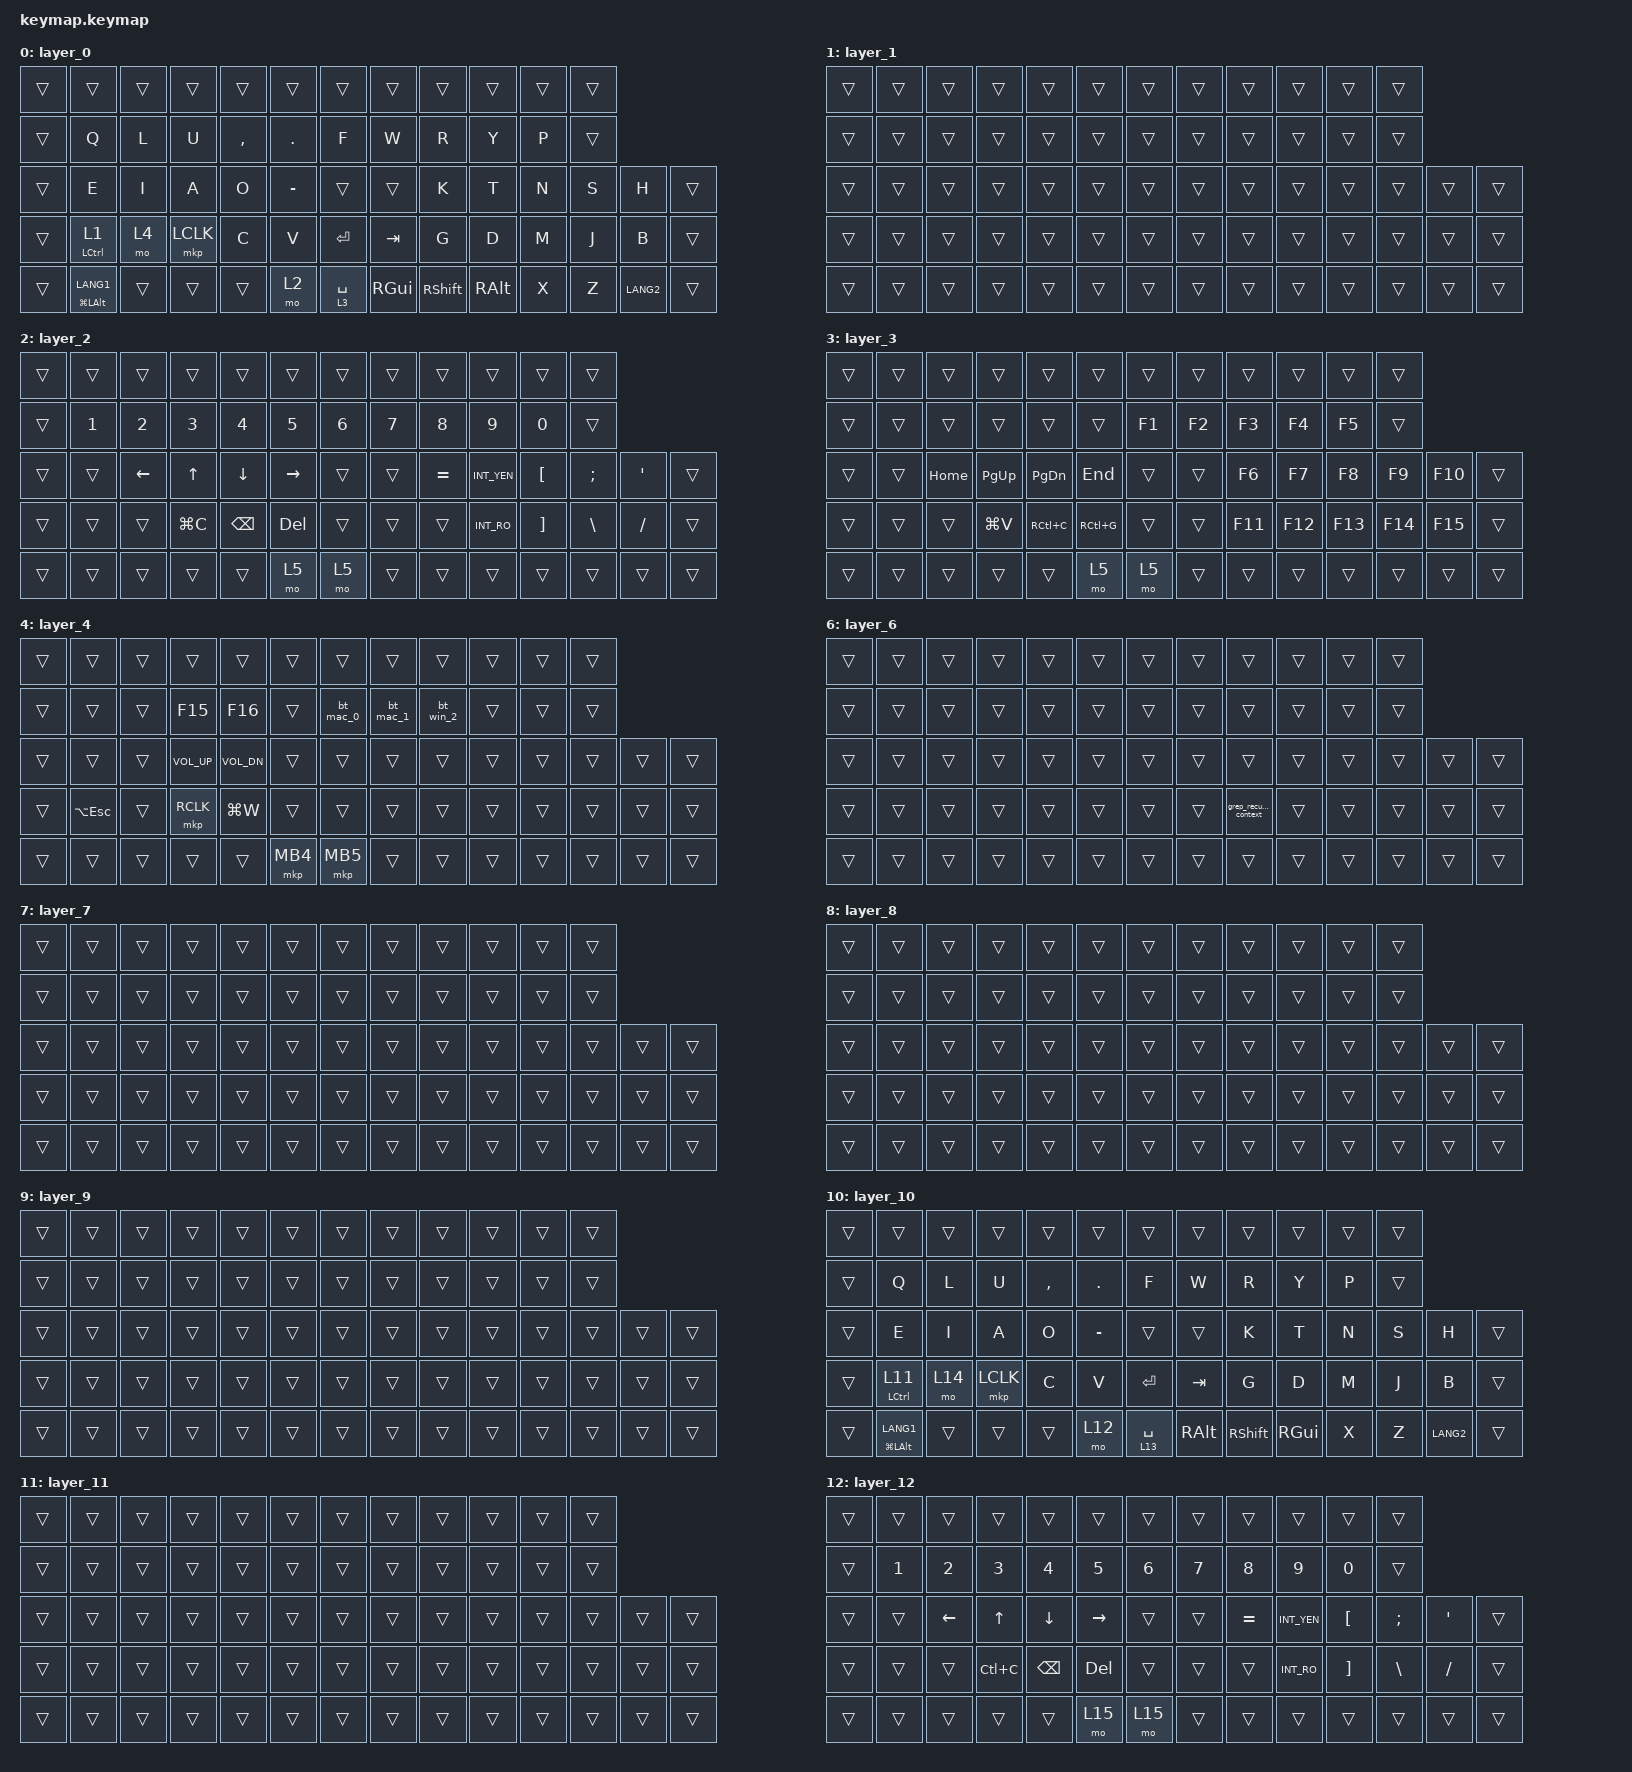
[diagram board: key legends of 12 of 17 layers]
#include <behaviors.dtsi>
#include <dt-bindings/zmk/bt.h>
#include <dt-bindings/zmk/keys.h>
#include <dt-bindings/zmk/outputs.h>
#include <dt-bindings/zmk/pointing.h>

/* ここで既存 behavior を上書き */
&mt {
    flavor = "hold-preferred";
    tapping-term-ms = <200>;
};

&lt {
    flavor = "hold-preferred";
    tapping-term-ms = <200>;
};

/ {
    behaviors {
        ctrl_or_scroll_toggle: ctrl_or_scroll_toggle {
            compatible = "zmk,behavior-hold-tap";
            #binding-cells = <2>;
            flavor = "hold-preferred";
            tapping-term-ms = <200>;
            bindings = <&kp>, <&tog>;
        };
    };

    macros {
        // Bluetooth プロファイル選択とOS別レイヤー切り替えを一度に行う。
        bt_mac_0: bt_mac_0 {
            compatible = "zmk,behavior-macro";
            #binding-cells = <0>;
            bindings = <&bt BT_SEL 0>, <&to 0>;
        };

        bt_mac_1: bt_mac_1 {
            compatible = "zmk,behavior-macro";
            #binding-cells = <0>;
            bindings = <&bt BT_SEL 1>, <&to 0>;
        };

        bt_win_2: bt_win_2 {
            compatible = "zmk,behavior-macro";
            #binding-cells = <0>;
            bindings = <&bt BT_SEL 2>, <&to 10>;
        };

        esc_eisu: esc_eisu {
            compatible = "zmk,behavior-macro";
            #binding-cells = <0>;
            bindings
                = <&macro_tap &kp ESCAPE>
                , <&macro_tap &kp LANG2>;
        };

        emacs_org_prefix: emacs_org_prefix {
            compatible = "zmk,behavior-macro";
            #binding-cells = <0>;
            bindings = <&macro_tap &kp LC(C) &kp LC(X)>;
        };

        // RDP 全画面でもローカルの仮想デスクトップを切り替える。
        // Ctrl、Altを先に押してからHomeを短く入力する（診断ブランチで短押し成功）。
        rdp_desktop_left: rdp_desktop_left {
            compatible = "zmk,behavior-macro";
            #binding-cells = <0>;
            wait-ms = <40>;
            tap-ms = <40>;
            bindings
                = <&macro_press &kp LCTRL &kp LALT>
                , <&macro_tap &kp HOME>
                , <&macro_release &kp LALT>
                , <&macro_wait_time 0>
                , <&kp LCTRL>
                , <&macro_wait_time 40>
                , <&macro_tap &kp LG(LC(LEFT))>;
        };

        rdp_desktop_right: rdp_desktop_right {
            compatible = "zmk,behavior-macro";
            #binding-cells = <0>;
            wait-ms = <40>;
            tap-ms = <40>;
            bindings
                = <&macro_press &kp LCTRL &kp LALT>
                , <&macro_tap &kp HOME>
                , <&macro_release &kp LALT>
                , <&macro_wait_time 0>
                , <&kp LCTRL>
                , <&macro_wait_time 40>
                , <&macro_tap &kp LG(LC(RIGHT))>;
        };

        grep_recursive_context: grep_recursive_context {
            compatible = "zmk,behavior-macro";
            #binding-cells = <0>;
            wait-ms = <5>;
            tap-ms = <5>;
            bindings
                = <&macro_tap &kp LANG2>
                , <&kp G &kp R &kp E &kp P>
                , <&kp SPACE>
                , <&kp MINUS &kp LS(R) &kp N &kp LS(C)>
                , <&kp SPACE &kp N2 &kp SPACE>
                , <&kp MINUS &kp MINUS &kp C &kp O &kp L &kp O &kp R &kp LS(MINUS) &kp A &kp U &kp T &kp O>
                , <&kp SPACE>;
        };
    };

    combos {
        compatible = "zmk,combos";

        ao_escape {
            bindings = <&kp ESCAPE>;
            key-positions = <12 13>;
            layers = <0 1 10 11>;
            timeout-ms = <30>;
        };

        tn_ctrl_x {
            bindings = <&kp LC(X)>;
            key-positions = <16 17>;
            layers = <0 1 10 11>;
            timeout-ms = <30>;
        };

        tn_ctrl_c {
            bindings = <&kp LC(C)>;
            key-positions = <16 17>;
            layers = <2 12>;
            timeout-ms = <30>;
        };

        tn_org_prefix {
            bindings = <&emacs_org_prefix>;
            key-positions = <16 17>;
            layers = <3 13>;
            timeout-ms = <30>;
        };

        ao_eisu_escape_eisu {
            bindings = <&esc_eisu>;
            key-positions = <12 13 39>;
            layers = <0 1 10 11>;
            timeout-ms = <30>;
        };

        aotn_escape_eisu {
            bindings = <&esc_eisu>;
            key-positions = <12 13 16 17>;
            layers = <0 1 10 11>;
            timeout-ms = <30>;
        };

        bt_clear {
            bindings = <&bt BT_CLR>;
            key-positions = <28 29>;
            layers = <3 13>;
        };
    };

    keymap {
        compatible = "zmk,keymap";

        layer_0 {
            bindings = <
                &trans  &trans  &trans  &trans  &trans  &trans  &trans  &trans  &trans  &trans  &trans  &trans
                &trans  &kp Q  &kp L  &kp U  &kp COMMA  &kp DOT  &kp F  &kp W  &kp R  &kp Y  &kp P  &trans
                &trans  &kp E  &kp I  &kp A  &kp O  &kp MINUS  &trans  &trans  &kp K  &kp T  &kp N  &kp S  &kp H  &trans
                &trans  &ctrl_or_scroll_toggle LCTRL 1  &mo 4  &mkp LCLK  &kp C  &kp V  &kp RET  &kp TAB  &kp G  &kp D  &kp M  &kp J  &kp B  &trans
                &trans  &mt LG(LALT) LANG1  &trans  &trans  &trans  &mo 2  &lt 3 SPACE  &kp RGUI  &kp RSHIFT  &kp RALT  &kp X  &kp Z  &kp LANG2  &trans
            >;
        };

        layer_1 {
            bindings = <
                &trans  &trans  &trans  &trans  &trans  &trans  &trans  &trans  &trans  &trans  &trans  &trans
                &trans  &trans  &trans  &trans  &trans  &trans  &trans  &trans  &trans  &trans  &trans  &trans
                &trans  &trans  &trans  &trans  &trans  &trans  &trans  &trans  &trans  &trans  &trans  &trans  &trans  &trans
                &trans  &trans  &trans  &trans  &trans  &trans  &trans  &trans  &trans  &trans  &trans  &trans  &trans  &trans
                &trans  &trans  &trans  &trans  &trans  &trans  &trans  &trans  &trans  &trans  &trans  &trans  &trans  &trans
            >;
        };

        layer_2 {
            bindings = <
                &trans  &trans  &trans  &trans  &trans  &trans  &trans  &trans  &trans  &trans  &trans  &trans
                &trans  &kp N1  &kp N2  &kp N3  &kp N4  &kp N5  &kp N6  &kp N7  &kp N8  &kp N9  &kp N0  &trans
                &trans  &trans  &kp LEFT  &kp UP_ARROW  &kp DOWN  &kp RIGHT  &trans  &trans  &kp EQUAL  &kp INT_YEN  &kp LBKT  &kp SEMI  &kp SQT  &trans
                &trans  &trans  &trans  &kp LG(C)  &kp BSPC  &kp DELETE  &trans  &trans  &trans  &kp INT_RO  &kp RBKT  &kp BSLH  &kp FSLH  &trans
                &trans  &trans  &trans  &trans  &trans  &mo 5  &mo 5  &trans  &trans  &trans  &trans  &trans  &trans  &trans
            >;
        };

        layer_3 {
            bindings = <
                &trans  &trans  &trans  &trans  &trans  &trans  &trans  &trans  &trans  &trans  &trans  &trans
                &trans  &trans  &trans  &trans  &trans  &trans  &kp F1  &kp F2  &kp F3  &kp F4  &kp F5  &trans
                &trans  &trans  &kp HOME  &kp PG_UP  &kp PAGE_DOWN  &kp END  &trans  &trans  &kp F6  &kp F7  &kp F8  &kp F9  &kp F10  &trans
                &trans  &trans  &trans  &kp LG(V)  &kp RC(C)  &kp RC(G)  &trans  &trans  &kp F11  &kp F12  &kp F13  &kp F14  &kp F15  &trans
                &trans  &trans  &trans  &trans  &trans  &mo 5  &mo 5  &trans  &trans  &trans  &trans  &trans  &trans  &trans
            >;
        };

        layer_4 {
            bindings = <
                &trans  &trans  &trans  &trans  &trans  &trans  &trans  &trans  &trans  &trans  &trans  &trans
                &trans  &trans  &trans  &kp F15  &kp F16  &trans  &bt_mac_0  &bt_mac_1  &bt_win_2  &trans  &trans  &trans
                &trans  &trans  &trans  &kp K_VOL_UP  &kp K_VOL_DN  &trans  &trans  &trans  &trans  &trans  &trans  &trans  &trans  &trans
                &trans  &kp LA(ESCAPE)  &trans  &mkp RCLK  &kp LG(W)  &trans  &trans  &trans  &trans  &trans  &trans  &trans  &trans  &trans
                &trans  &trans  &trans  &trans  &trans  &mkp MB4  &mkp MB5  &trans  &trans  &trans  &trans  &trans  &trans  &trans
            >;
        };

        layer_5 {
            bindings = <
                &trans  &trans  &trans  &trans  &trans  &trans  &trans  &trans  &trans  &trans  &trans  &trans
                &trans  &kp LC(LG(LA(Q)))  &kp LC(LG(LA(L)))  &kp LC(LG(LA(U)))  &kp LC(LG(LA(COMMA)))  &kp LC(LG(LA(DOT)))  &kp LC(LG(LA(F)))  &kp LC(LG(LA(W)))  &kp LC(LG(LA(R)))  &kp LC(LG(LA(Y)))  &kp LC(LG(LA(P)))  &trans
                &trans  &kp LC(LG(LA(E)))  &kp LC(LG(LA(I)))  &kp LC(LG(LA(A)))  &kp LC(LG(LA(O)))  &kp LC(LG(LA(MINUS)))  &trans  &trans  &kp LC(LG(LA(K)))  &kp LC(LG(LA(T)))  &kp LC(LG(LA(N)))  &kp LC(LG(LA(S)))  &kp LC(LG(LA(H)))  &trans
                &trans  &trans  &trans  &trans  &kp LC(LG(LA(C)))  &kp LC(LG(LA(V)))  &kp LC(LG(LA(RET)))  &kp LC(LG(LA(TAB)))  &kp LC(LG(LA(G)))  &kp LC(LG(LA(D)))  &kp LC(LG(LA(M)))  &kp LC(LG(LA(J)))  &kp LC(LG(LA(B)))  &trans
                &trans  &trans  &trans  &trans  &trans  &trans  &trans  &trans  &trans  &trans  &kp LC(LG(LA(X)))  &kp LC(LG(LA(Z)))  &trans  &trans
            >;
        };

        layer_6 {
            bindings = <
                &trans  &trans  &trans  &trans  &trans  &trans  &trans  &trans  &trans  &trans  &trans  &trans
                &trans  &trans  &trans  &trans  &trans  &trans  &trans  &trans  &trans  &trans  &trans  &trans
                &trans  &trans  &trans  &trans  &trans  &trans  &trans  &trans  &trans  &trans  &trans  &trans  &trans  &trans
                &trans  &trans  &trans  &trans  &trans  &trans  &trans  &trans  &grep_recursive_context  &trans  &trans  &trans  &trans  &trans
                &trans  &trans  &trans  &trans  &trans  &trans  &trans  &trans  &trans  &trans  &trans  &trans  &trans  &trans
            >;
        };
        // 7〜9は番号を維持するための未使用レイヤー。
        layer_7 {
            bindings = <
                &trans  &trans  &trans  &trans  &trans  &trans  &trans  &trans  &trans  &trans  &trans  &trans
                &trans  &trans  &trans  &trans  &trans  &trans  &trans  &trans  &trans  &trans  &trans  &trans
                &trans  &trans  &trans  &trans  &trans  &trans  &trans  &trans  &trans  &trans  &trans  &trans  &trans  &trans
                &trans  &trans  &trans  &trans  &trans  &trans  &trans  &trans  &trans  &trans  &trans  &trans  &trans  &trans
                &trans  &trans  &trans  &trans  &trans  &trans  &trans  &trans  &trans  &trans  &trans  &trans  &trans  &trans
            >;
        };

        layer_8 {
            bindings = <
                &trans  &trans  &trans  &trans  &trans  &trans  &trans  &trans  &trans  &trans  &trans  &trans
                &trans  &trans  &trans  &trans  &trans  &trans  &trans  &trans  &trans  &trans  &trans  &trans
                &trans  &trans  &trans  &trans  &trans  &trans  &trans  &trans  &trans  &trans  &trans  &trans  &trans  &trans
                &trans  &trans  &trans  &trans  &trans  &trans  &trans  &trans  &trans  &trans  &trans  &trans  &trans  &trans
                &trans  &trans  &trans  &trans  &trans  &trans  &trans  &trans  &trans  &trans  &trans  &trans  &trans  &trans
            >;
        };

        layer_9 {
            bindings = <
                &trans  &trans  &trans  &trans  &trans  &trans  &trans  &trans  &trans  &trans  &trans  &trans
                &trans  &trans  &trans  &trans  &trans  &trans  &trans  &trans  &trans  &trans  &trans  &trans
                &trans  &trans  &trans  &trans  &trans  &trans  &trans  &trans  &trans  &trans  &trans  &trans  &trans  &trans
                &trans  &trans  &trans  &trans  &trans  &trans  &trans  &trans  &trans  &trans  &trans  &trans  &trans  &trans
                &trans  &trans  &trans  &trans  &trans  &trans  &trans  &trans  &trans  &trans  &trans  &trans  &trans  &trans
            >;
        };

        // Windows 用レイヤー（Mac の 0〜6 を複製）。
        layer_10 {
            bindings = <
                &trans  &trans  &trans  &trans  &trans  &trans  &trans  &trans  &trans  &trans  &trans  &trans
                &trans  &kp Q  &kp L  &kp U  &kp COMMA  &kp DOT  &kp F  &kp W  &kp R  &kp Y  &kp P  &trans
                &trans  &kp E  &kp I  &kp A  &kp O  &kp MINUS  &trans  &trans  &kp K  &kp T  &kp N  &kp S  &kp H  &trans
                &trans  &ctrl_or_scroll_toggle LCTRL 11  &mo 14  &mkp LCLK  &kp C  &kp V  &kp RET  &kp TAB  &kp G  &kp D  &kp M  &kp J  &kp B  &trans
                &trans  &mt LG(LALT) LANG1  &trans  &trans  &trans  &mo 12  &lt 13 SPACE  &kp RALT  &kp RSHIFT  &kp RGUI  &kp X  &kp Z  &kp LANG2  &trans
            >;
        };

        layer_11 {
            bindings = <
                &trans  &trans  &trans  &trans  &trans  &trans  &trans  &trans  &trans  &trans  &trans  &trans
                &trans  &trans  &trans  &trans  &trans  &trans  &trans  &trans  &trans  &trans  &trans  &trans
                &trans  &trans  &trans  &trans  &trans  &trans  &trans  &trans  &trans  &trans  &trans  &trans  &trans  &trans
                &trans  &trans  &trans  &trans  &trans  &trans  &trans  &trans  &trans  &trans  &trans  &trans  &trans  &trans
                &trans  &trans  &trans  &trans  &trans  &trans  &trans  &trans  &trans  &trans  &trans  &trans  &trans  &trans
            >;
        };

        layer_12 {
            bindings = <
                &trans  &trans  &trans  &trans  &trans  &trans  &trans  &trans  &trans  &trans  &trans  &trans
                &trans  &kp N1  &kp N2  &kp N3  &kp N4  &kp N5  &kp N6  &kp N7  &kp N8  &kp N9  &kp N0  &trans
                &trans  &trans  &kp LEFT  &kp UP_ARROW  &kp DOWN  &kp RIGHT  &trans  &trans  &kp EQUAL  &kp INT_YEN  &kp LBKT  &kp SEMI  &kp SQT  &trans
                &trans  &trans  &trans  &kp LC(C)  &kp BSPC  &kp DELETE  &trans  &trans  &trans  &kp INT_RO  &kp RBKT  &kp BSLH  &kp FSLH  &trans
                &trans  &trans  &trans  &trans  &trans  &mo 15  &mo 15  &trans  &trans  &trans  &trans  &trans  &trans  &trans
            >;
        };

        layer_13 {
            bindings = <
                &trans  &trans  &trans  &trans  &trans  &trans  &trans  &trans  &trans  &trans  &trans  &trans
                &trans  &trans  &trans  &trans  &trans  &trans  &kp F1  &kp F2  &kp F3  &kp F4  &kp F5  &trans
                &trans  &trans  &kp HOME  &kp PG_UP  &kp PAGE_DOWN  &kp END  &trans  &trans  &kp F6  &kp F7  &kp F8  &kp F9  &kp F10  &trans
                &trans  &trans  &trans  &kp LC(V)  &kp RC(C)  &kp RC(G)  &trans  &trans  &kp F11  &kp F12  &kp F13  &kp F14  &kp F15  &trans
                &trans  &trans  &trans  &trans  &trans  &mo 15  &mo 15  &trans  &trans  &trans  &trans  &trans  &trans  &trans
            >;
        };

        layer_14 {
            bindings = <
                &trans  &trans  &trans  &trans  &trans  &trans  &trans  &trans  &trans  &trans  &trans  &trans
                &trans  &trans  &trans  &kp F15  &kp F16  &trans  &bt_mac_0  &bt_mac_1  &bt_win_2  &trans  &trans  &trans
                &trans  &trans  &trans  &kp K_VOL_UP  &kp K_VOL_DN  &trans  &trans  &trans  &trans  &trans  &trans  &trans  &trans  &trans
                &trans  &kp LA(ESCAPE)  &trans  &mkp RCLK  &kp LC(W)  &trans  &trans  &trans  &trans  &trans  &trans  &trans  &trans  &trans
                &trans  &trans  &trans  &trans  &trans  &mkp MB4  &mkp MB5  &trans  &trans  &trans  &trans  &trans  &trans  &trans
            >;
        };

        layer_15 {
            bindings = <
                &trans  &trans  &trans  &trans  &trans  &trans  &trans  &trans  &trans  &trans  &trans  &trans
                &trans  &trans  &trans  &trans  &trans  &trans  &kp LG(N1)  &kp LG(N2)  &kp LG(N3)  &kp LG(N4)  &kp LG(N5)  &trans
                &trans  &trans  &trans  &trans  &trans  &trans  &trans  &trans  &kp LG(N6)  &kp LG(N7)  &kp LG(N8)  &kp LG(N9)  &kp LG(N0)  &trans
                &trans  &trans  &trans  &trans  &rdp_desktop_left  &rdp_desktop_right  &trans  &trans  &trans  &trans  &trans  &trans  &trans  &trans
                &trans  &trans  &trans  &trans  &trans  &trans  &trans  &trans  &trans  &trans  &trans  &trans  &trans  &trans
            >;
        };

        layer_16 {
            bindings = <
                &trans  &trans  &trans  &trans  &trans  &trans  &trans  &trans  &trans  &trans  &trans  &trans
                &trans  &trans  &trans  &trans  &trans  &trans  &trans  &trans  &trans  &trans  &trans  &trans
                &trans  &trans  &trans  &trans  &trans  &trans  &trans  &trans  &trans  &trans  &trans  &trans  &trans  &trans
                &trans  &trans  &trans  &trans  &trans  &trans  &trans  &trans  &grep_recursive_context  &trans  &trans  &trans  &trans  &trans
                &trans  &trans  &trans  &trans  &trans  &trans  &trans  &trans  &trans  &trans  &trans  &trans  &trans  &trans
            >;
        };
    };
};
